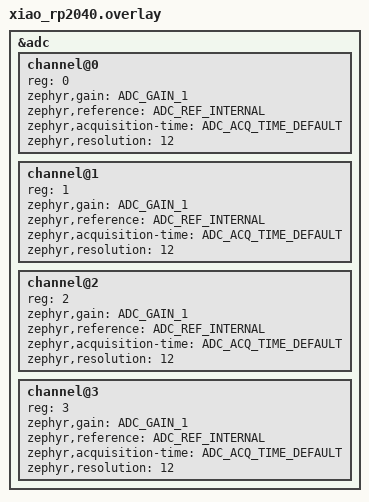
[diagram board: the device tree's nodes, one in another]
#include "rp2040_storage_partition.dtsi"
#include "rp2040_xosc_startup_delay.dtsi"

xiao_adc: &adc {
    #address-cells = <1>;
    #size-cells = <0>;

    channel@0 {
        reg = <0>; /* D0, GPIO26 */
        zephyr,gain = "ADC_GAIN_1";
        zephyr,reference = "ADC_REF_INTERNAL";
        zephyr,acquisition-time = <ADC_ACQ_TIME_DEFAULT>;
        zephyr,resolution = <12>;
    };

    channel@1 {
        reg = <1>; /* D1, GPIO27 */
        zephyr,gain = "ADC_GAIN_1";
        zephyr,reference = "ADC_REF_INTERNAL";
        zephyr,acquisition-time = <ADC_ACQ_TIME_DEFAULT>;
        zephyr,resolution = <12>;
    };

    channel@2 {
        reg = <2>; /* D2, GPIO28 */
        zephyr,gain = "ADC_GAIN_1";
        zephyr,reference = "ADC_REF_INTERNAL";
        zephyr,acquisition-time = <ADC_ACQ_TIME_DEFAULT>;
        zephyr,resolution = <12>;
    };

    channel@3 {
        reg = <3>; /* D3, GPIO29 */
        zephyr,gain = "ADC_GAIN_1";
        zephyr,reference = "ADC_REF_INTERNAL";
        zephyr,acquisition-time = <ADC_ACQ_TIME_DEFAULT>;
        zephyr,resolution = <12>;
    };
};
